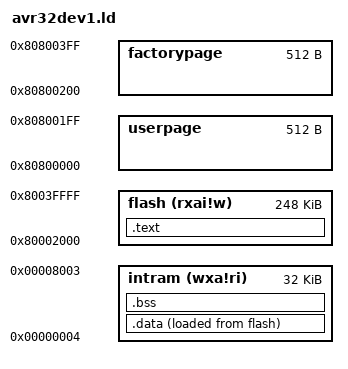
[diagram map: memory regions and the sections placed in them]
/****************************************************************************
 * boards/avr/at32uc3/avr32dev1/scripts/avr32dev1.ld
 *
 * Licensed to the Apache Software Foundation (ASF) under one or more
 * contributor license agreements.  See the NOTICE file distributed with
 * this work for additional information regarding copyright ownership.  The
 * ASF licenses this file to you under the Apache License, Version 2.0 (the
 * "License"); you may not use this file except in compliance with the
 * License.  You may obtain a copy of the License at
 *
 *   http://www.apache.org/licenses/LICENSE-2.0
 *
 * Unless required by applicable law or agreed to in writing, software
 * distributed under the License is distributed on an "AS IS" BASIS, WITHOUT
 * WARRANTIES OR CONDITIONS OF ANY KIND, either express or implied.  See the
 * License for the specific language governing permissions and limitations
 * under the License.
 *
 ****************************************************************************/

ENTRY(_stext)

/* The following assumes that the bootloader resides at 0x8000:0000 and so
 * links the application to execute after the bootloader at 0x8000:2000.
 * To link so that NuttX boots directly without using the bootloader,
 * change the flash definition to:
 *
 *   flash (rxai!w)  : ORIGIN = 0x80000000, LENGTH = 256K
 */

MEMORY
{
  flash (rxai!w)  : ORIGIN = 0x80002000, LENGTH = 256K - 8K
  intram (wxa!ri) : ORIGIN = 0x00000004, LENGTH = 32K
  userpage        : ORIGIN = 0x80800000, LENGTH = 512
  factorypage     : ORIGIN = 0x80800200, LENGTH = 512
}

SECTIONS
{
    .text : {
        _stext = ABSOLUTE(.);
        *(.vectors)
        *(.text .text.*)
        *(.fixup)
        *(.gnu.warning)
        *(.rodata .rodata.*)
        *(.gnu.linkonce.t.*)
        *(.glue_7)
        *(.glue_7t)
        *(.got)
        *(.gcc_except_table)
        *(.gnu.linkonce.r.*)
        _etext = ABSOLUTE(.);
    } > flash

    _eronly = ABSOLUTE(.);      /* See below                    */

    .data : {
        _sdata = ABSOLUTE(.);
        *(.data .data.*)
        *(.gnu.linkonce.d.*)
        CONSTRUCTORS
        . = ALIGN(4);
        _edata = ABSOLUTE(.);
    } > intram AT > flash

    .bss : {            /* BSS              */
        _sbss = ABSOLUTE(.);
        *(.bss .bss.*)
        *(.gnu.linkonce.b.*)
        *(COMMON)
        . = ALIGN(4);
        _ebss = ABSOLUTE(.);
    } > intram
    /* Stabs debugging sections.    */
    .stab 0 : { *(.stab) }
    .stabstr 0 : { *(.stabstr) }
    .stab.excl 0 : { *(.stab.excl) }
    .stab.exclstr 0 : { *(.stab.exclstr) }
    .stab.index 0 : { *(.stab.index) }
    .stab.indexstr 0 : { *(.stab.indexstr) }
    .comment 0 : { *(.comment) }
    .debug_abbrev 0 : { *(.debug_abbrev) }
    .debug_info 0 : { *(.debug_info) }
    .debug_line 0 : { *(.debug_line) }
    .debug_pubnames 0 : { *(.debug_pubnames) }
    .debug_aranges 0 : { *(.debug_aranges) }
}
